# STM32F413 register map
File version: 1.9
CPU: CM4 r0p1, little endian, MPU, FPU, 4 interrupt priority bits
Registers are 32-bit, read-write, reset 0x0 unless marked. A register's access mark holds for its fields unless they carry their own. Offsets are from the block's base; [hi:lo] are bit positions; {n}, {i} and the like mark numbered series; 'fields as' and 'values as' point back to an identical list.

## FSMC — Flexible static memory controller
Base 0xA0000000
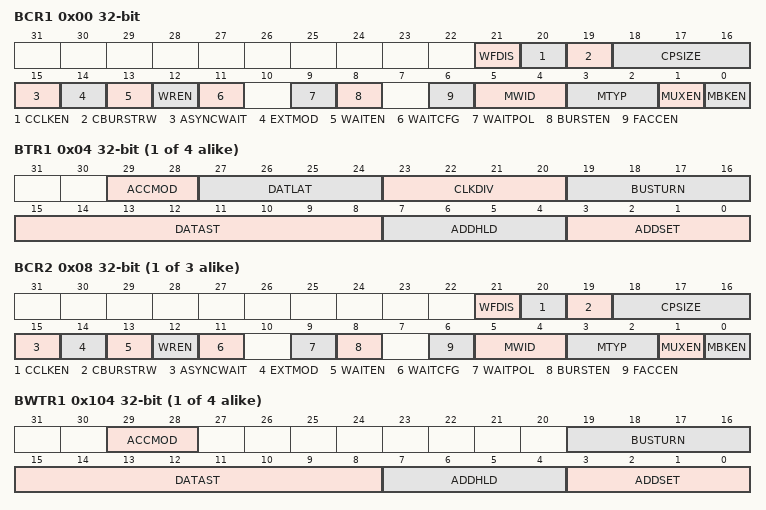
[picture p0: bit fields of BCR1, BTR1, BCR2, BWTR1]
0x00 BCR1
  [21] WFDIS — Write FIFO Disable
    0=Enabled (Write FIFO enabled); 1=Disabled (Write FIFO disabled)
  [20] CCLKEN — Continuous Clock Enable
    0=Disabled (The FMC_CLK is generated continuously during asynchronous and synchronous access. The FMC_CLK clock is activated when the CCLKEN is set); 1=Enabled (The FMC_CLK is only generated during the synchronous memory access (read/write transaction))
  [19] CBURSTRW — Write burst enable
    0=Disabled (Write operations are always performed in asynchronous mode); 1=Enabled (Write operations are performed in synchronous mode)
  [18:16] CPSIZE — CRAM page size
    0=No burst split when crossing page boundary; 1=Bytes128 (128 bytes CRAM page size); 2=Bytes256 (256 bytes CRAM page size); 3=Bytes512 (512 bytes CRAM page size); 4=Bytes1024 (1024 bytes CRAM page size)
  [15] ASYNCWAIT — Wait signal during asynchronous transfers
    0=Disabled (Wait signal not used in asynchronous mode); 1=Enabled (Wait signal used even in asynchronous mode)
  [14] EXTMOD — Extended mode enable
    0=Disabled (Values inside the FMC_BWTR are not taken into account); 1=Enabled (Values inside the FMC_BWTR are taken into account)
  [13] WAITEN — Wait enable bit
    0=Disabled (Values inside the FMC_BWTR are taken into account); 1=Enabled (NWAIT signal enabled)
  [12] WREN — Write enable bitWREN
    0=Disabled (Write operations disabled for the bank by the FMC); 1=Enabled (Write operations enabled for the bank by the FMC)
  [11] WAITCFG — Wait timing configuration
    0=BeforeWaitState (NWAIT signal is active one data cycle before wait state); 1=DuringWaitState (NWAIT signal is active during wait state)
  [9] WAITPOL — Wait signal polarity bit
    0=ActiveLow (NWAIT active low); 1=ActiveHigh (NWAIT active high)
  [8] BURSTEN — Burst enable bit
    0=Disabled (Burst mode disabled); 1=Enabled (Burst mode enabled)
  [6] FACCEN — Flash access enable
    0=Disabled (Corresponding NOR Flash memory access is disabled); 1=Enabled (Corresponding NOR Flash memory access is enabled)
  [5:4] MWID — Memory data bus width
    0=Bits8 (Memory data bus width 8 bits); 1=Bits16 (Memory data bus width 16 bits); 2=Bits32 (Memory data bus width 32 bits)
  [3:2] MTYP — Memory type
    0=SRAM (SRAM memory type); 1=PSRAM (PSRAM (CRAM) memory type); 2=Flash (NOR Flash/OneNAND Flash)
  [1] MUXEN — Memory bank enable bit
    0=Disabled (Address/Data non-multiplexed); 1=Enabled (Address/Data multiplexed on databus)
  [0] MBKEN — Memory bank enable bit
    0=Disabled (Corresponding memory bank is disabled); 1=Enabled (Corresponding memory bank is enabled)
0x04 BTR{i} (i=1..4; step 0x8) — BTR{i}
  [29:28] ACCMOD — Access mode
    0=A (Access mode A); 1=B (Access mode B); 2=C (Access mode C); 3=D (Access mode D)
  [27:24] DATLAT — Data latency
  [23:20] CLKDIV range 1..15 — Clock divide ratio
  [19:16] BUSTURN — Bus turnaround phase duration
  [15:8] DATAST range 1..255 — Data-phase duration
  [7:4] ADDHLD range 1..15 — Address-hold phase duration
  [3:0] ADDSET — Address setup phase duration
0x08 BCR{i} (i=2..4; step 0x8) — BCR{i}
  [21] WFDIS — Write FIFO Disable
  [20] CCLKEN — Continuous Clock Enable
  [19] CBURSTRW — Write burst enable
    values as BCR1.CBURSTRW
  [18:16] CPSIZE — CRAM page size
    values as BCR1.CPSIZE
  [15] ASYNCWAIT — Wait signal during asynchronous transfers
    values as BCR1.ASYNCWAIT
  [14] EXTMOD — Extended mode enable
    values as BCR1.EXTMOD
  [13] WAITEN — Wait enable bit
    values as BCR1.WAITEN
  [12] WREN — Write enable bit
    values as BCR1.WREN
  [11] WAITCFG — Wait timing configuration
    values as BCR1.WAITCFG
  [9] WAITPOL — Wait signal polarity bit
    values as BCR1.WAITPOL
  [8] BURSTEN — Burst enable bit
    values as BCR1.BURSTEN
  [6] FACCEN — Flash access enable
    values as BCR1.FACCEN
  [5:4] MWID — Memory data bus width
    values as BCR1.MWID
  [3:2] MTYP — Memory type
    values as BCR1.MTYP
  [1] MUXEN — Address/data multiplexing enable bit
    values as BCR1.MUXEN
  [0] MBKEN — Memory bank enable bit
    values as BCR1.MBKEN
{0xFC+8i} BWTR{i} (i=1..4) — BWTR{i}
  [29:28] ACCMOD — Access mode
    values as BTR{i}.ACCMOD
  [19:16] BUSTURN — Bus turnaround phase duration
  [15:8] DATAST range 1..255 — Data-phase duration
  [7:4] ADDHLD range 1..15 — Address-hold phase duration
  [3:0] ADDSET — Address setup phase duration
